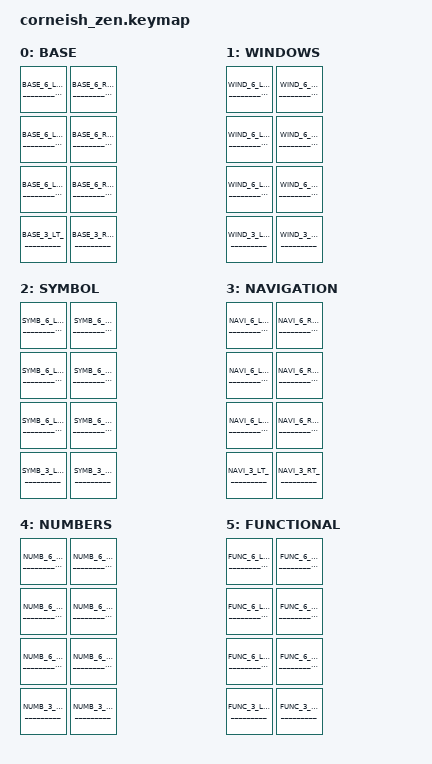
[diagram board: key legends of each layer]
// vim:fileencoding=utf-8:foldmethod=marker

#include <behaviors.dtsi>
#include <dt-bindings/zmk/keys.h>
#include <dt-bindings/zmk/bt.h>

#include "layout.keymap"

#define TAPPING_TERM 170
#define QUICK_TAP    150

#define HRML(k1,k2,k3,k4) &lhm LSHFT k1  &lhm LALT k2  &lhm LCTRL k3  &lhm LGUI k4
#define HRMR(k1,k2,k3,k4) &rhm RGUI k1  &rhm RCTRL k2  &rhm RALT k3  &rhm RSHFT k4
#define HT(k1,k2,k3,k4) &ht LG(V) k1  &ht LG(C) k2  &ht LG(X) k3  &ht LG(Z) k4

// -----------------------------------------------------------------------------------------
// | TAB   0 | Q  1 | W   2 | E    3 | R    4 | T    5 |   | Y    6 | U    7 | I    8 | O  9 | P 10 | BKSP 11 |
// | CTRL 12 | A 13 | S  14 | D   15 | F   16 | G   17 |   | H   18 | J   19 | K   20 | L 21 | ; 22 |  '   23 |
// | SHFT 24 | Z 25 | X  26 | C   27 | V   28 | B   29 |   | N   30 | M   31 | ,   32 | . 33 | / 34 | ESC  35 |
//                          | GUI 36 | LWR 37 | SPC 38 |   | ENT 39 | RSE 40 | ALT 41 |

/ {
  chosen {
    zmk,matrix_transform = &default_transform;
  };
};

&lt {
  quick-tap-ms = <QUICK_TAP>;
};

&mt {
  global-quick-tap;
};

#define COMBO_TERM 25
#define LONG_COMBO_TERM 50

/ {
        conditional_layers {
            compatible = "zmk,conditional-layers";
            tri_layer {
                if-layers = <NAVI SYMB>;
                then-layer = <NUMB>;
            };
        };

        combos {
          compatible = "zmk,combos";

          combo_fun {
            timeout-ms = <150>;
            key-positions = <37 40>;
            bindings = <&mo FUNC>;
          };

          // HomeRow Combos {{{

          combo_a_scln {
            timeout-ms = <COMBO_TERM>;
            key-positions = <13 22>;
            bindings = <&sk LCTRL>;
          };
          combo_sl {
            timeout-ms = <COMBO_TERM>;
            key-positions = <14 21>;
            bindings = <&sk LALT>;
          };
          combo_dk {
            timeout-ms = <COMBO_TERM>;
            key-positions = <15 20>;
            bindings = <&sk LGUI>;
          };
          combo_fj {
            timeout-ms = <COMBO_TERM>;
            key-positions = <16 19>;
            bindings = <&sk LSHIFT>;
          };

          // Left Half {{{
          combo_as {
            timeout-ms = <COMBO_TERM>;
            key-positions = <13 14>;
            bindings = <&kp LA(LCTRL)>;
          };
          combo_ad {
            timeout-ms = <COMBO_TERM>;
            key-positions = <13 15>;
            bindings = <&kp LG(LCTRL)>;
          };
          combo_af {
            timeout-ms = <COMBO_TERM>;
            key-positions = <13 16>;
            bindings = <&kp LS(LCTRL)>;
          };
          combo_sd {
            timeout-ms = <COMBO_TERM>;
            key-positions = <14 15>;
            bindings = <&kp LG(LALT)>;
          };
          combo_sf {
            timeout-ms = <COMBO_TERM>;
            key-positions = <14 16>;
            bindings = <&kp LS(LALT)>;
          };
          combo_df {
            timeout-ms = <COMBO_TERM>;
            key-positions = <15 16>;
            bindings = <&kp LS(LGUI)>;
          };

          combo_sdf {
            timeout-ms = <COMBO_TERM>;
            key-positions = <14 15 16>;
            bindings = <&kp LA(LS(LGUI))>;
          };
          combo_adf {
            timeout-ms = <COMBO_TERM>;
            key-positions = <13 15 16>;
            bindings = <&kp LC(LS(LGUI))>;
          };
          combo_asf {
            timeout-ms = <COMBO_TERM>;
            key-positions = <13 14 16>;
            bindings = <&kp LC(LA(LGUI))>;
          };
          combo_asd {
            timeout-ms = <COMBO_TERM>;
            key-positions = <13 14 15>;
            bindings = <&kp LC(LA(LSHFT))>;
          };

          combo_asdf {
            timeout-ms = <COMBO_TERM>;
            key-positions = <13 14 15 16>;
            bindings = <&kp LC(LA(LS(LGUI)))>;
          };

          // }}}

          // Right Half {{{
          combo_jk {
            timeout-ms = <COMBO_TERM>;
            key-positions = <19 20>;
            bindings = <&kp LG(LSHIFT)>;
          };
          combo_jl {
            timeout-ms = <COMBO_TERM>;
            key-positions = <19 21>;
            bindings = <&kp LA(LSHIFT)>;
          };
          combo_j_scln {
            timeout-ms = <COMBO_TERM>;
            key-positions = <19 22>;
            bindings = <&kp LC(LSHIFT)>;
          };
          combo_kl {
            timeout-ms = <COMBO_TERM>;
            key-positions = <20 21>;
            bindings = <&kp LA(LGUI)>;
          };
          combo_k_scln {
            timeout-ms = <COMBO_TERM>;
            key-positions = <20 22>;
            bindings = <&kp LC(LGUI)>;
          };
          combo_l_scln {
            timeout-ms = <COMBO_TERM>;
            key-positions = <21 22>;
            bindings = <&kp LC(LALT)>;
          };

          combo_jkl {
            timeout-ms = <COMBO_TERM>;
            key-positions = <19 20 21>;
            bindings = <&kp LA(LG(LSHIFT))>;
          };
          combo_jk_scln {
            timeout-ms = <COMBO_TERM>;
            key-positions = <19 20 22>;
            bindings = <&kp LC(LG(LSHIFT))>;
          };
          combo_jl_scln {
            timeout-ms = <COMBO_TERM>;
            key-positions = <19 21 22>;
            bindings = <&kp LC(LA(LSHIFT))>;
          };
          combo_kl_scln {
            timeout-ms = <COMBO_TERM>;
            key-positions = <20 21 22>;
            bindings = <&kp LC(LA(LGUI))>;
          };

          combo_jkl_scln {
            timeout-ms = <COMBO_TERM>;
            key-positions = <19 20 21 22>;
            bindings = <&kp LC(LA(LG(LSHIFT)))>;
          };
          // }}}

          // }}}
        };


        behaviors {
          ht: hold_tap {
            label = "hold_tap";
            compatible = "zmk,behavior-hold-tap";
            #binding-cells = <2>;
            flavor = "balanced";
            tapping-term-ms = <TAPPING_TERM>;
            quick-tap-ms = <QUICK_TAP>;
            bindings = <&kp>, <&kp>;
          };

          lhm: left_hand_homerow_mods {
            compatible = "zmk,behavior-hold-tap";
            label = "LEFT_HOMEROW_MODS";
            #binding-cells = <2>;
            flavor = "balanced";
            tapping-term-ms = <TAPPING_TERM>;
            quick-tap-ms = <QUICK_TAP>;
            require-prior-idle-ms = <150>;
            bindings = <&kp>, <&kp>;
            hold-trigger-key-positions = <6 7 8 9 10 11 15 16 18 19 20 21 22 23 30 31 32 33 34>;
            hold-trigger-on-release;
          };

          rhm: right_hand_homerow_mods {
            compatible = "zmk,behavior-hold-tap";
            label = "RIGHT_HOMEROW_MODS";
            #binding-cells = <2>;
            flavor = "balanced";
            tapping-term-ms = <TAPPING_TERM>;
            quick-tap-ms = <QUICK_TAP>;
            require-prior-idle-ms = <150>;
            bindings = <&kp>, <&kp>;
            hold-trigger-key-positions = <0 1 2 3 4 5 12 13 14 15 16 17 19 20 21 22 24 25 26 27 28 29>;
            hold-trigger-on-release;
          };

          sw_app: switch_application {
            compatible = "zmk,behavior-tri-state";
            label = "SWITCH_APP";
            #binding-cells = <0>;
            bindings = <&kt LGUI>, <&kp TAB>, <&kt LGUI>;
            ignored-key-positions = <1 18 19 20 21>;
          };

          sw_win: switch_window {
            compatible = "zmk,behavior-tri-state";
            label = "SWITCH_WIN";
            #binding-cells = <0>;
            bindings = <&kt LGUI>, <&kp GRAVE>, <&kt LGUI>;
          };

          sw_lang: switch_language {
            compatible = "zmk,behavior-tri-state";
            label = "SWITCH_LANG";
            #binding-cells = <0>;
            bindings = <&kt LGUI>, <&kp SPACE>, <&kt LGUI>;
          };
        };


        keymap {
                compatible = "zmk,keymap";

                base_layer {
                        label = "BASE";
                        bindings = <
  _________________BASE_6_L1_________________  _________________BASE_6_R1_________________
  _________________BASE_6_L2_________________  _________________BASE_6_R2_________________
  _________________BASE_6_L3_________________  _________________BASE_6_R3_________________
               __________BASE_3_LT___________  __________BASE_3_RT___________
                        >;
                };

                windows_layer {
                        label = "WINDOWS";
                        bindings = <
  _________________WIND_6_L1_________________  _________________WIND_6_R1_________________
  _________________WIND_6_L2_________________  _________________WIND_6_R2_________________
  _________________WIND_6_L3_________________  _________________WIND_6_R3_________________
               __________WIND_3_LT___________  __________WIND_3_RT___________
                        >;
                };

                symbol_layer {
                        label = "SYMBOL";
                        bindings = <
  _________________SYMB_6_L1_________________  _________________SYMB_6_R1_________________
  _________________SYMB_6_L2_________________  _________________SYMB_6_R2_________________
  _________________SYMB_6_L3_________________  _________________SYMB_6_R3_________________
               __________SYMB_3_LT___________  __________SYMB_3_RT___________
                        >;
                };

                navigation_layer {
                        label = "NAVIGATION";
                        bindings = <
  _________________NAVI_6_L1_________________  _________________NAVI_6_R1_________________
  _________________NAVI_6_L2_________________  _________________NAVI_6_R2_________________
  _________________NAVI_6_L3_________________  _________________NAVI_6_R3_________________
               __________NAVI_3_LT___________  __________NAVI_3_RT___________
                        >;
                };

                numbers_layer {
                        label = "NUMBERS";
                        bindings = <
  _________________NUMB_6_L1_________________  _________________NUMB_6_R1_________________
  _________________NUMB_6_L2_________________  _________________NUMB_6_R2_________________
  _________________NUMB_6_L3_________________  _________________NUMB_6_R3_________________
               __________NUMB_3_LT___________  __________NUMB_3_RT___________
                        >;
                };

                functional_layer {
                        label = "FUNCTIONAL";
                        bindings = <
  _________________FUNC_6_L1_________________  _________________FUNC_6_R1_________________
  _________________FUNC_6_L2_________________  _________________FUNC_6_R2_________________
  _________________FUNC_6_L3_________________  _________________FUNC_6_R3_________________
               __________FUNC_3_LT___________  __________FUNC_3_RT___________
                        >;
                };
        };
};

